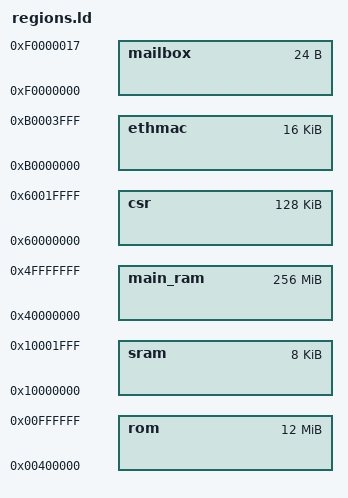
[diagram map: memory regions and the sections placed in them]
MEMORY {
	sram : ORIGIN = 0x10000000, LENGTH = 0x00002000
	csr : ORIGIN = 0x60000000, LENGTH = 0x00020000
	main_ram : ORIGIN = 0x40000000, LENGTH = 0x10000000
	rom : ORIGIN = 0x00400000, LENGTH = 0x00c00000
	ethmac : ORIGIN = 0xb0000000, LENGTH = 0x00004000
	mailbox : ORIGIN = 0xf0000000, LENGTH = 0x00000018
}
